# B6x register map
Vendor: XiaoMan; Series: B6 SOC; File version: 20260307
CPU: CM0+ r0p0, little endian, no MPU, no FPU, 2 interrupt priority bits
Registers are 32-bit, read-write, reset 0x0 unless marked. A register's access mark holds for its fields unless they carry their own. Offsets are from the block's base; [hi:lo] are bit positions; {n}, {i} and the like mark numbered series.

## DMA
Base 0x40026000
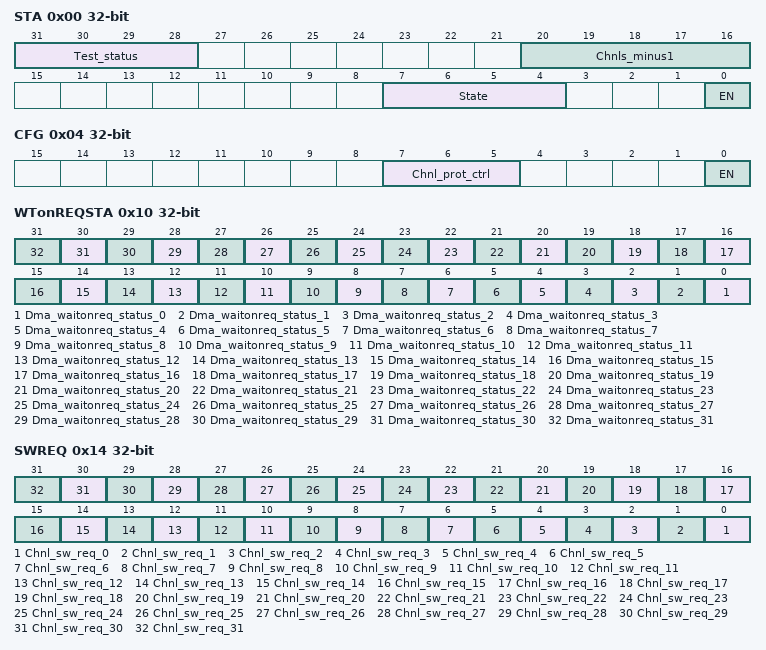
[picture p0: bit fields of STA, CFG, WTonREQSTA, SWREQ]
0x00 STA — DMA Status Register.
  [31:28] Test_status
  [20:16] Chnls_minus1 — Numbers of available DMA channels minus one.
  [7:4] State — Current state of the control state machine.
  [0] EN — Enable status of the controller.
0x04 CFG — DMA Configuration Register.
  [7:5] Chnl_prot_ctrl — Sets the AHB-Lite protection by controlling the HPROT[3:1] signal levels.
  [0] EN — Enable status of the controller.
0x08 CTRLBASEPTR — Channel Control Data Base Pointer.
  [31:5] Ctrl_base_ptr — Pointer to the base address of the primary data structure.
0x0C ALTCTRLBASEPTR — Channel Alternate Control Data Base Pointer.
  [31:0] ALTCTRLBASEPTR — Base address of the alternate data structure.This register will read as CTRL_BASE_PTR+0x80.
0x10 WTonREQSTA — Channel Wait On Request Status.
  [n] Dma_waitonreq_status_{n} (n=0..31) — Channel wait on request status.
0x14 SWREQ — Channel Software Request.
  [n] Chnl_sw_req_{n} (n=0..31) — Set the appropriate bit to generate a software DMA request on the corresponding DMA channel.
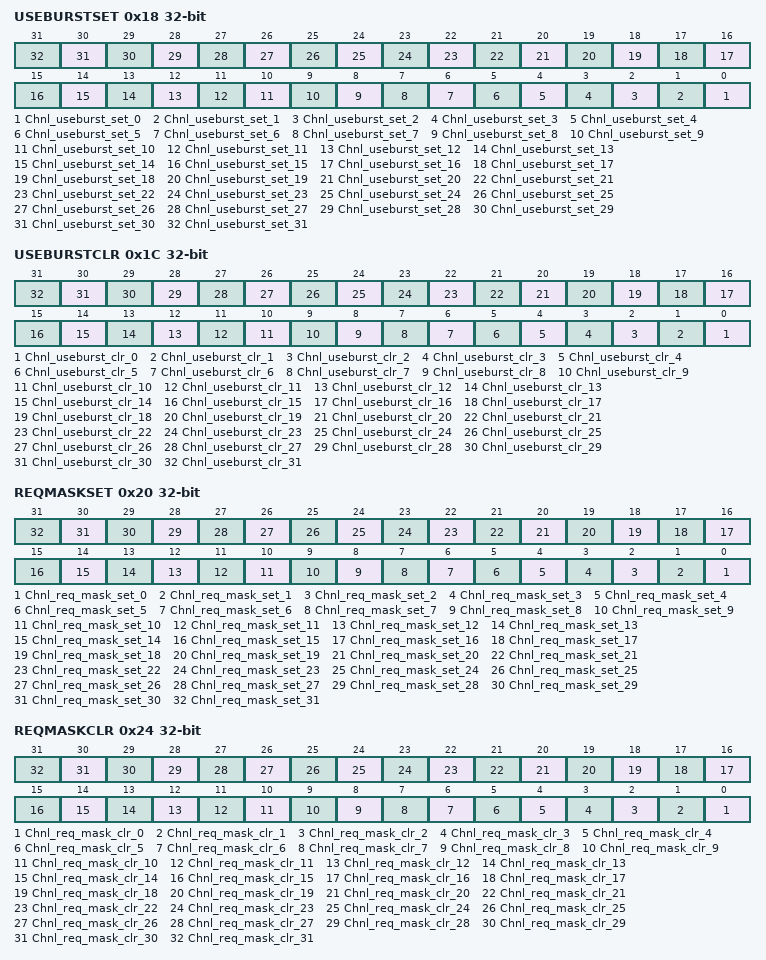
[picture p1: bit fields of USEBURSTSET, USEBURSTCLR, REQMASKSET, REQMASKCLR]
0x18 USEBURSTSET — Channel Useburst Set.
  [n] Chnl_useburst_set_{n} (n=0..31) — Returns the useburst status, or disables dma_sreq[C] from generating DMA requests.
0x1C USEBURSTCLR — Channel Useburst Clear.
  [n] Chnl_useburst_clr_{n} (n=0..31) — Set the appropriate bit to enable dma_sreq[] to generate requests.
0x20 REQMASKSET — Channel Request Mask Set.
  [n] Chnl_req_mask_set_{n} (n=0..31) — Set the appropriate bit to enable DMA requests for the channel corresponding to dma_req[] and dma_sreq[].
0x24 REQMASKCLR — Channel Request Mask Clear.
  [n] Chnl_req_mask_clr_{n} (n=0..31) — Returns the request mask status of dma_req[] and dma_sreq[], or disables the corresponding channel from generating DMA requests.
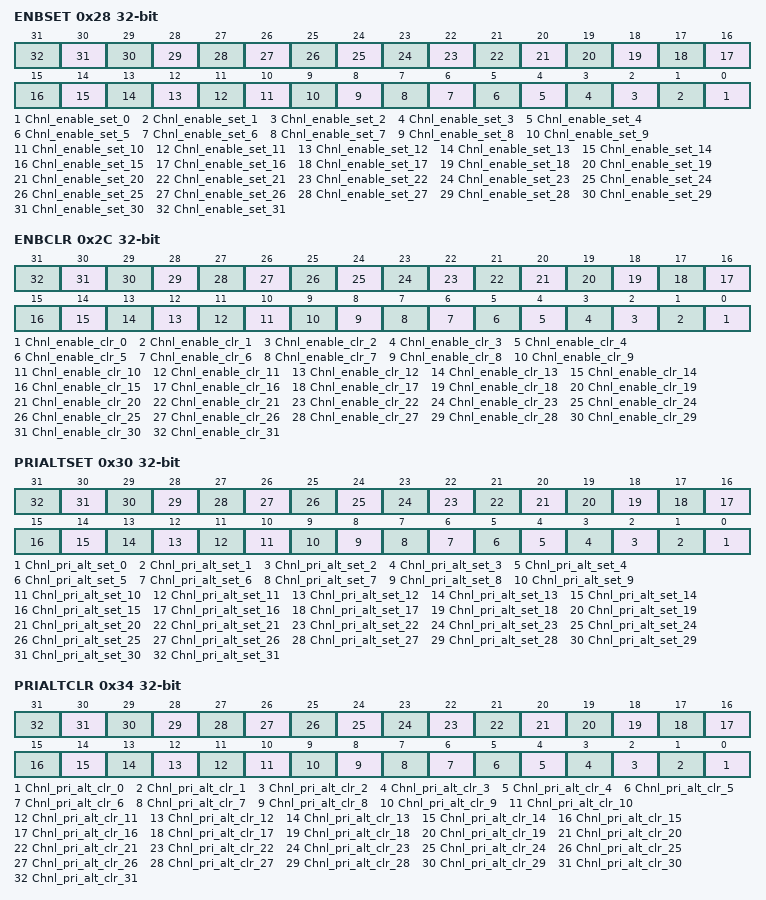
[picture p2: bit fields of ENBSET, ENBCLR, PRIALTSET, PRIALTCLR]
0x28 ENBSET — Channel Enable Set.
  [n] Chnl_enable_set_{n} (n=0..31) — Returns the enable status of the channels, or enables the corresponding channels.
0x2C ENBCLR — Channel Useburst Clear.
  [n] Chnl_enable_clr_{n} (n=0..31) — Set the appropriate bit to disable the corresponding DMA channel.
0x30 PRIALTSET — Channel Primary-Alternate Set.
  [n] Chnl_pri_alt_set_{n} (n=0..31) — Returns the channel control data structure status, or selects the alternate data structure for the corresponding DMA channel.
0x34 PRIALTCLR — Channel Primary-Alternate Clear.
  [n] Chnl_pri_alt_clr_{n} (n=0..31) — Set the appropriate bit to select the primary data structure for the corresponding DMA channel.
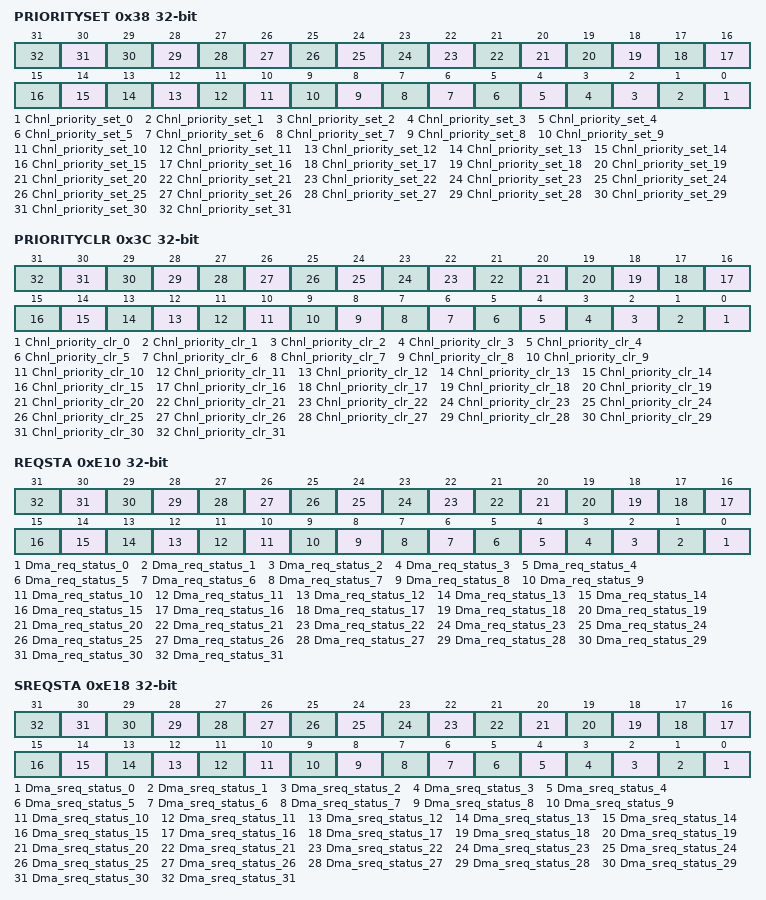
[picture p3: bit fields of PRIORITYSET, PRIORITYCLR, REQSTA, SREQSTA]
0x38 PRIORITYSET — Channel Priority Set.
  [n] Chnl_priority_set_{n} (n=0..31) — Returns the channel priority mask status, or sets the channel priority to high.
0x3C PRIORITYCLR — Channel Priority Clear.
  [n] Chnl_priority_clr_{n} (n=0..31) — Set the appropriate bit to select the default priority level for the specified DMA channel.
0x40 RESERVED0[3] read-modifies — Reserved, must be kept at reset value.
0x4C ERRCLR — Bus Error Clear.
  [0] Err_clr — Returns the status of dma_err, or sets the signal LOW.
0x50 RESERVED1[876] read-modifies — Reserved, must be kept at reset value.
0xE00 INTGRCFG — Integration Configuration.
  [0] Int_test_en — Data length selection.
{0xDF4+8i} RESERVED{i}[1] read-modifies (i=2..5) — Reserved, must be kept at reset value.
0xE08 STALLSTA — DMA Stall Status.
  [0] Dma_stall_status — Data length selection.
0xE10 REQSTA — DMA Request Status.
  [n] Dma_req_status_{n} (n=0..31) — Data length selection.
0xE18 SREQSTA — DMA Single Request Status.
  [n] Dma_sreq_status_{n} (n=0..31) — Data length selection.
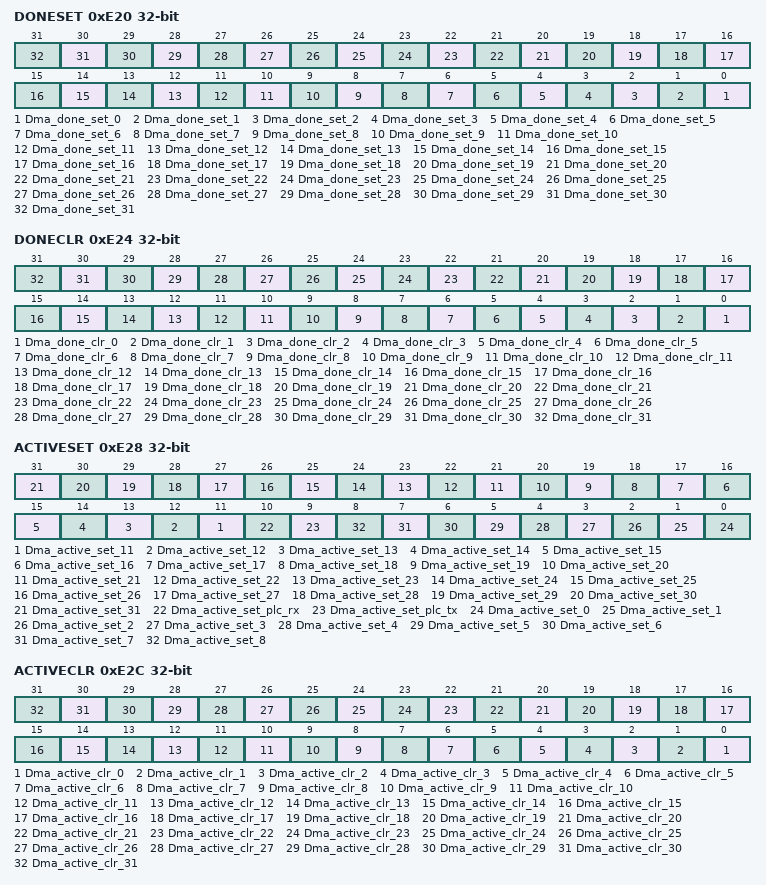
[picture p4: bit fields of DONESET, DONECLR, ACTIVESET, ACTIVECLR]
0xE20 DONESET — DMA Done Set.
  [n] Dma_done_set_{n} (n=0..31) — Data length selection.
0xE24 DONECLR — DMA Done Clear.
  [n] Dma_done_clr_{n} (n=0..31) — Data length selection.
0xE28 ACTIVESET — DMA Active Set.
  [n] Dma_active_set_{n} (n=11..31) — Data length selection.
  [10] Dma_active_set_plc_rx — Data length selection.
  [9] Dma_active_set_plc_tx — Data length selection.
  [n] Dma_active_set_{n} (n=0..8) — Data length selection.
0xE2C ACTIVECLR — DMA Active Clear.
  [n] Dma_active_clr_{n} (n=0..31) — Data length selection.
0xE30 RESERVED6[5] read-modifies — Reserved, must be kept at reset value.
0xE48 ERRSET — Bus Error Set.
  [0] Err_set — Data length selection.
